# STM32F7x6 register map
File version: 1.3
CPU: CM7 r0p0, little endian, no MPU, no FPU, 3 interrupt priority bits
Registers are 32-bit, read-write, reset 0x0 unless marked. A register's access mark holds for its fields unless they carry their own. Offsets are from the block's base; [hi:lo] are bit positions; {n}, {i} and the like mark numbered series.

## DWT — Data Watchpoint and Trace
Base 0xE0001000
0x00 CTRL access not given — Control Register
0x04 CYCCNT access not given — Cycle Count Register
0x08 CPICNT 8-bit access not given — CPI Count Register
0x0C EXCCNT 8-bit access not given — Exception Overhead Count Register
0x10 SLEEPCNT 8-bit access not given — Sleep Count Register
0x14 LSUCNT 8-bit access not given — LSU Count Register
0x18 FOLDCNT 8-bit access not given — Folded-instruction Count Register
0x1C PCSR access not given — Program Counter Sample Register
0xFB0 LAR access not given — Lock Access Register
0xFB4 LSR access not given — Lock Status Register

## RNG — Random number generator
Base 0x50060800
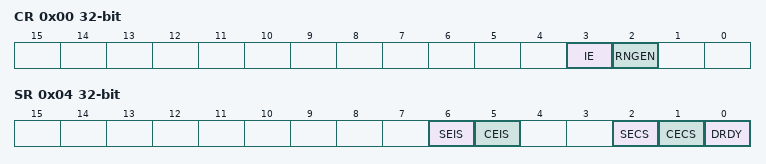
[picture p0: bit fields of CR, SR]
0x00 CR — control register
  [3] IE — Interrupt enable
  [2] RNGEN — Random number generator enable
0x04 SR access per field — status register
  [6] SEIS rw — Seed error interrupt status
  [5] CEIS rw — Clock error interrupt status
  [2] SECS ro — Seed error current status
  [1] CECS ro — Clock error current status
  [0] DRDY ro — Data ready
0x08 DR ro — data register
  [31:0] RNDATA — Random data

## HASH — Hash processor
Base 0x50060400
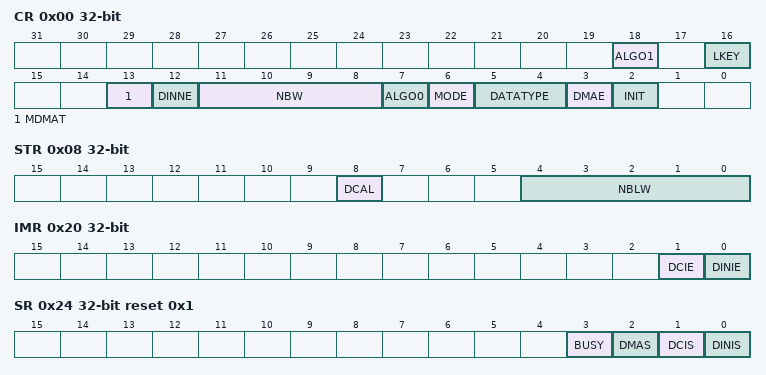
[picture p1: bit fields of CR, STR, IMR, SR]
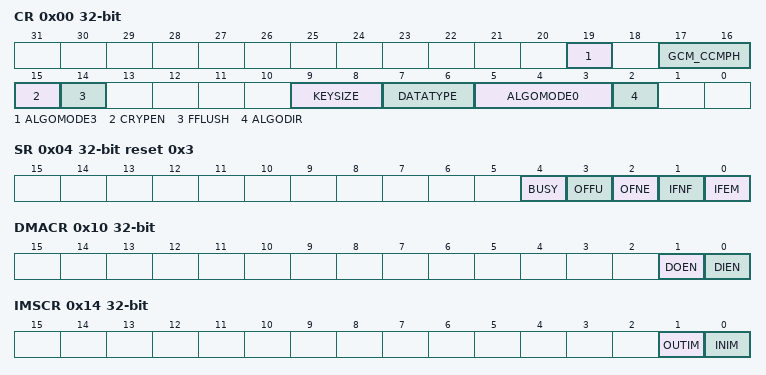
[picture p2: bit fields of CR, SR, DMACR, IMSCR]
0x00 CR access per field — control register
  [18] ALGO1 rw — ALGO
  [16] LKEY rw — Long key selection
  [13] MDMAT rw — Multiple DMA Transfers
  [12] DINNE ro — DIN not empty
  [11:8] NBW ro — Number of words already pushed
  [7] ALGO0 rw — Algorithm selection
  [6] MODE rw — Mode selection
  [5:4] DATATYPE rw — Data type selection
  [3] DMAE rw — DMA enable
  [2] INIT wo — Initialize message digest calculation
0x04 DIN — data input register
  [31:0] DATAIN — Data input
0x08 STR access per field — start register
  [8] DCAL wo — Digest calculation
  [4:0] NBLW rw — Number of valid bits in the last word of the message
{0xC+4i} HR{i} ro (i=0..4) — digest registers
  [31:0] H{i}
0x20 IMR — interrupt enable register
  [1] DCIE — Digest calculation completion interrupt enable
  [0] DINIE — Data input interrupt enable
0x24 SR access per field reset 0x1 — status register
  [3] BUSY ro — Busy bit
  [2] DMAS ro — DMA Status
  [1] DCIS rw — Digest calculation completion interrupt status
  [0] DINIS rw — Data input interrupt status
{0xF8+4i} CSR{i} (i=0..53) — context swap registers
0x310 HASH_HR0 ro — HASH digest register
  [31:0] H0
{0x310+4i} HASH_HR{i} ro (i=1..7) — read-only
  [31:0] H{i}

## CRYP — Cryptographic processor
Base 0x50060000
0x00 CR access per field — control register
  [19] ALGOMODE3 rw — ALGOMODE
  [17:16] GCM_CCMPH rw
  [15] CRYPEN rw — Cryptographic processor enable
  [14] FFLUSH wo — FIFO flush
  [9:8] KEYSIZE rw — Key size selection (AES mode only)
  [7:6] DATATYPE rw — Data type selection
  [5:3] ALGOMODE0 rw — Algorithm mode
  [2] ALGODIR rw — Algorithm direction
0x04 SR ro reset 0x3 — status register
  [4] BUSY — Busy bit
  [3] OFFU — Output FIFO full
  [2] OFNE — Output FIFO not empty
  [1] IFNF — Input FIFO not full
  [0] IFEM — Input FIFO empty
0x08 DIN — data input register
  [31:0] DATAIN — Data input
0x0C DOUT ro — data output register
  [31:0] DATAOUT — Data output
0x10 DMACR — DMA control register
  [1] DOEN — DMA output enable
  [0] DIEN — DMA input enable
0x14 IMSCR — interrupt mask set/clear register
  [1] OUTIM — Output FIFO service interrupt mask
  [0] INIM — Input FIFO service interrupt mask
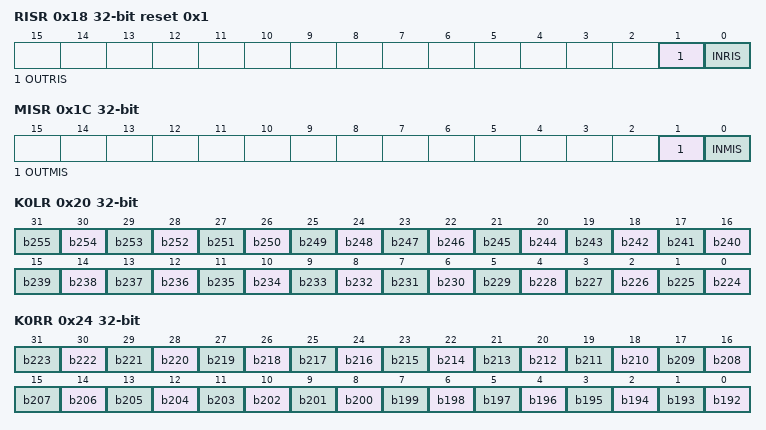
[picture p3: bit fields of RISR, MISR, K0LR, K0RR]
0x18 RISR ro reset 0x1 — raw interrupt status register
  [1] OUTRIS — Output FIFO service raw interrupt status
  [0] INRIS — Input FIFO service raw interrupt status
0x1C MISR ro — masked interrupt status register
  [1] OUTMIS — Output FIFO service masked interrupt status
  [0] INMIS — Input FIFO service masked interrupt status
0x20 K0LR wo — key registers
  [n-224] b{n} (n=224..255)
0x24 K0RR wo — key registers
  [n-192] b{n} (n=192..223)
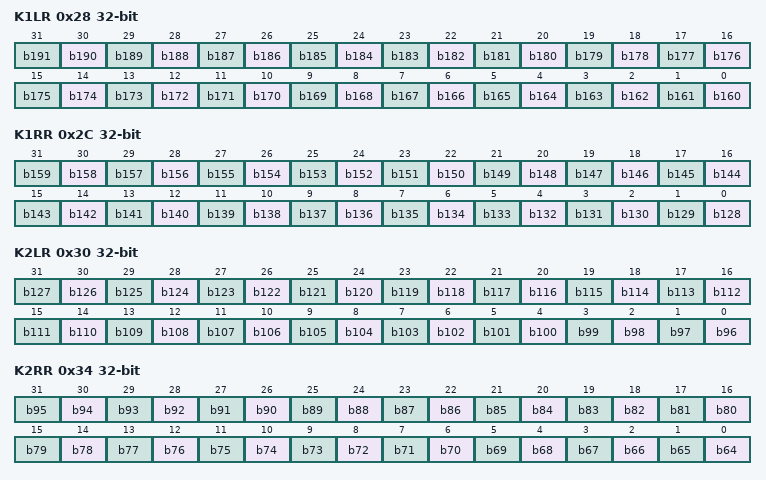
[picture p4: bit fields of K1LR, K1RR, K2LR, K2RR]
0x28 K1LR wo — key registers
  [n-160] b{n} (n=160..191)
0x2C K1RR wo — key registers
  [n-128] b{n} (n=128..159)
0x30 K2LR wo — key registers
  [n-96] b{n} (n=96..127)
0x34 K2RR wo — key registers
  [n-64] b{n} (n=64..95)
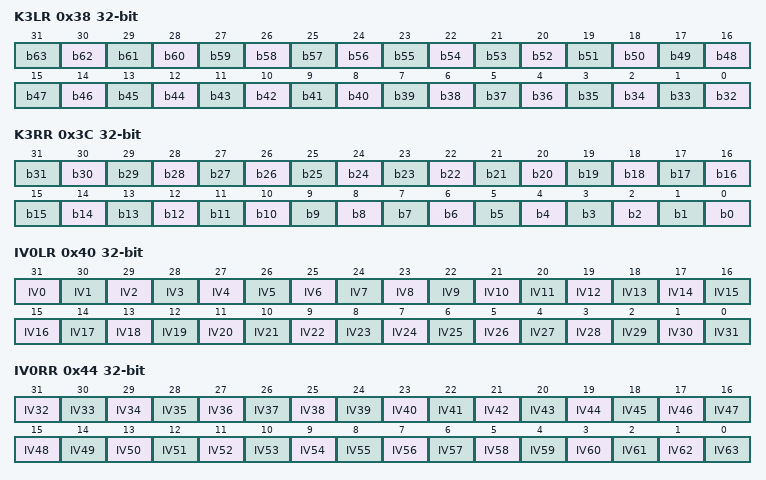
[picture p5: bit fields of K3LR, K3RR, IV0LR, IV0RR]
0x38 K3LR wo — key registers
  [n-32] b{n} (n=32..63)
0x3C K3RR wo — key registers
  [n] b{n} (n=0..31)
0x40 IV0LR — initialization vector registers
  [31-n] IV{n} (n=0..31)
0x44 IV0RR — initialization vector registers
  [63-n] IV{n} (n=32..63)
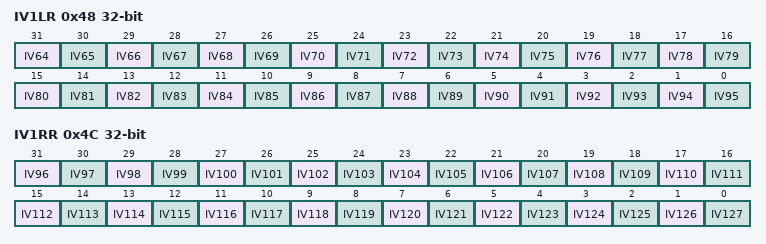
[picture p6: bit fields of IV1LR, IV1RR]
0x48 IV1LR — initialization vector registers
  [95-n] IV{n} (n=64..95)
0x4C IV1RR — initialization vector registers
  [127-n] IV{n} (n=96..127)
{0x50+4i} CSGCMCCM{i}R (i=0..7) — context swap register
{0x70+4i} CSGCM{i}R (i=0..7) — context swap register
